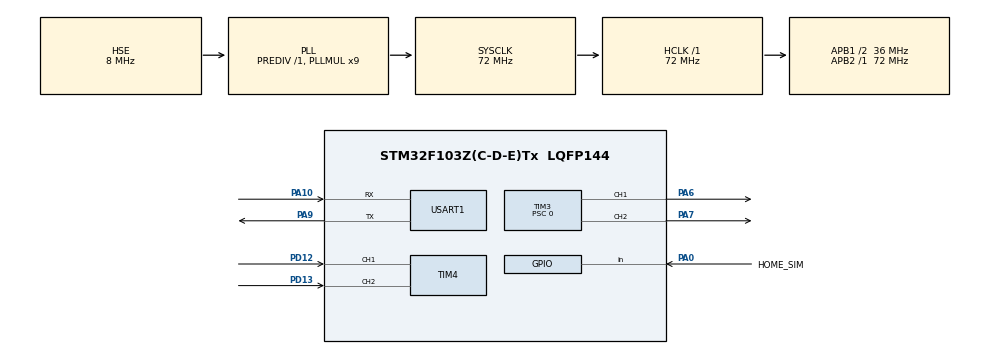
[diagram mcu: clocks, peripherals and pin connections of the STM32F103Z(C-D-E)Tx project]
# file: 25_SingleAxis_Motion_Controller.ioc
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FREERTOS.Tasks01=Motion_Task_,24,512,Motion_Task,Default,NULL,Dynamic,NULL,NULL
Mcu.Family=STM32F1
Mcu.Name=STM32F103Z(C-D-E)Tx
Mcu.Package=LQFP144
NVIC.PriorityGroup=NVIC_PRIORITYGROUP_4
NVIC.TIM6_IRQn=true\:15\:0\:false\:false\:true\:false\:false\:true\:true
NVIC.TimeBase=TIM6_IRQn
NVIC.TimeBaseIP=TIM6
OSC_IN.Mode=HSE-External-Oscillator
OSC_IN.Signal=RCC_OSC_IN
OSC_OUT.Mode=HSE-External-Oscillator
OSC_OUT.Signal=RCC_OSC_OUT
PA0-WKUP.GPIO_Label=HOME_SIM
PA0-WKUP.GPIO_PuPd=GPIO_PULLDOWN
PA0-WKUP.Signal=GPIO_Input
PA10.Mode=Asynchronous
PA10.Signal=USART1_RX
PA13.Mode=Serial_Wire
PA13.Signal=SYS_JTMS-SWDIO
PA14.Mode=Serial_Wire
PA14.Signal=SYS_JTCK-SWCLK
PA6.Signal=S_TIM3_CH1
PA7.Signal=S_TIM3_CH2
PA9.Mode=Asynchronous
PA9.Signal=USART1_TX
PD12.Signal=S_TIM4_CH1
PD13.Signal=S_TIM4_CH2
ProjectManager.HeapSize=0x200
ProjectManager.StackSize=0x400
ProjectManager.TargetToolchain=STM32CubeIDE
RCC.AHBFreq_Value=72000000
RCC.APB1CLKDivider=RCC_HCLK_DIV2
RCC.APB1Freq_Value=36000000
RCC.APB1TimFreq_Value=72000000
RCC.APB2Freq_Value=72000000
RCC.APB2TimFreq_Value=72000000
RCC.HCLKFreq_Value=72000000
RCC.PLLMUL=RCC_PLL_MUL9
RCC.PLLSourceVirtual=RCC_PLLSOURCE_HSE
RCC.SYSCLKFreq_VALUE=72000000
RCC.SYSCLKSource=RCC_SYSCLKSOURCE_PLLCLK
RCC.USBFreq_Value=72000000
SH.S_TIM3_CH1.0=TIM3_CH1,PWM Generation1 CH1
SH.S_TIM3_CH2.0=TIM3_CH2,PWM Generation2 CH2
SH.S_TIM4_CH1.0=TIM4_CH1,Encoder_Interface
SH.S_TIM4_CH2.0=TIM4_CH2,Encoder_Interface
TIM3.AutoReloadPreload=TIM_AUTORELOAD_PRELOAD_ENABLE
TIM3.Channel-PWM\ Generation1\ CH1=TIM_CHANNEL_1
TIM3.Channel-PWM\ Generation2\ CH2=TIM_CHANNEL_2
TIM3.Period=3599
TIM3.Prescaler=0
TIM4.EncoderMode=TIM_ENCODERMODE_TI12
TIM4.IC1Filter=5
TIM4.IC2Filter=5
TIM4.IC2Polarity=TIM_ICPOLARITY_RISING
USART1.VirtualMode=VM_ASYNC
VP_FREERTOS_VS_CMSIS_V2.Mode=CMSIS_V2
VP_SYS_VS_tim6.Mode=TIM6
VP_TIM3_VS_ClockSourceINT.Mode=Internal
board=custom

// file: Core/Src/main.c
/* USER CODE BEGIN Header */
/**
  ******************************************************************************
  * @file           : main.c
  * @brief          : Main program body
  ******************************************************************************
  * @attention
  *
  * Copyright (c) 2026 STMicroelectronics.
  * All rights reserved.
  *
  * This software is licensed under terms that can be found in the LICENSE file
  * in the root directory of this software component.
  * If no LICENSE file comes with this software, it is provided AS-IS.
  *
  ******************************************************************************
  */
/* USER CODE END Header */
#include "main.h"
#include "cmsis_os.h"
#include "tim.h"
#include "usart.h"
#include "gpio.h"

void SystemClock_Config(void);
void MX_FREERTOS_Init(void);

int main(void)
{

  /* MCU Configuration--------------------------------------------------------*/

  /* Reset of all peripherals, Initializes the Flash interface and the Systick. */
  HAL_Init();

  /* Configure the system clock */
  SystemClock_Config();

  /* Initialize all configured peripherals */
  MX_GPIO_Init();
  MX_USART1_UART_Init();
  MX_TIM3_Init();
  MX_TIM4_Init();

  /* Init scheduler */
  osKernelInitialize();

  /* Call init function for freertos objects (in cmsis_os2.c) */
  MX_FREERTOS_Init();

  /* Start scheduler */
  osKernelStart();

  /* We should never get here as control is now taken by the scheduler */

  /* Infinite loop */
  while (1)
  {

  }
}

void SystemClock_Config(void)
{
  RCC_OscInitTypeDef RCC_OscInitStruct = {0};
  RCC_ClkInitTypeDef RCC_ClkInitStruct = {0};

  /** Initializes the RCC Oscillators according to the specified parameters
  * in the RCC_OscInitTypeDef structure.
  */
  RCC_OscInitStruct.OscillatorType = RCC_OSCILLATORTYPE_HSE;
  RCC_OscInitStruct.HSEState = RCC_HSE_ON;
  RCC_OscInitStruct.HSEPredivValue = RCC_HSE_PREDIV_DIV1;
  RCC_OscInitStruct.HSIState = RCC_HSI_ON;
  RCC_OscInitStruct.PLL.PLLState = RCC_PLL_ON;
  RCC_OscInitStruct.PLL.PLLSource = RCC_PLLSOURCE_HSE;
  RCC_OscInitStruct.PLL.PLLMUL = RCC_PLL_MUL9;
  if (HAL_RCC_OscConfig(&RCC_OscInitStruct) != HAL_OK)
  {
    Error_Handler();
  }

  /** Initializes the CPU, AHB and APB buses clocks
  */
  RCC_ClkInitStruct.ClockType = RCC_CLOCKTYPE_HCLK|RCC_CLOCKTYPE_SYSCLK
                              |RCC_CLOCKTYPE_PCLK1|RCC_CLOCKTYPE_PCLK2;
  RCC_ClkInitStruct.SYSCLKSource = RCC_SYSCLKSOURCE_PLLCLK;
  RCC_ClkInitStruct.AHBCLKDivider = RCC_SYSCLK_DIV1;
  RCC_ClkInitStruct.APB1CLKDivider = RCC_HCLK_DIV2;
  RCC_ClkInitStruct.APB2CLKDivider = RCC_HCLK_DIV1;

  if (HAL_RCC_ClockConfig(&RCC_ClkInitStruct, FLASH_LATENCY_2) != HAL_OK)
  {
    Error_Handler();
  }
}

void HAL_TIM_PeriodElapsedCallback(TIM_HandleTypeDef *htim)
{
  if (htim->Instance == TIM6)
  {
    HAL_IncTick();
  }
}

void Error_Handler(void)
{
  __disable_irq();
  while (1)
  {
  }
}

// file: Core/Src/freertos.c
/* USER CODE BEGIN Header */
/**
  ******************************************************************************
  * File Name          : freertos.c
  * Description        : Code for freertos applications
  ******************************************************************************
  */
/* USER CODE END Header */

#include "main.h"
#include "cmsis_os.h"

/* USER CODE BEGIN Includes */
#include "motion.h"
/* USER CODE END Includes */

/* Definitions for Motion_Task_ */
osThreadId_t Motion_Task_Handle;
const osThreadAttr_t Motion_Task__attributes = {
  .name = "Motion_Task_",
  .stack_size = 512 * 4,
  .priority = (osPriority_t) osPriorityNormal,
};

void Motion_Task(void *argument);
void MX_FREERTOS_Init(void); /* (MISRA C 2004 rule 8.1) */

void MX_FREERTOS_Init(void)
{
  /* USER CODE BEGIN Init */
	// 在创建任务前完成运动模块的外设启动与状态清零
	Motion_Init();

  /* USER CODE END Init */

  /* Create the thread(s) */
  /* creation of Motion_Task_ */
  Motion_Task_Handle = osThreadNew(Motion_Task, NULL, &Motion_Task__attributes);
}

void Motion_Task(void *argument)
{
  /* USER CODE BEGIN Motion_Task */
	// osDelayUntil 使用绝对 tick，避免循环执行耗时逐步累积成周期漂移
	uint32_t next_wake_tick = osKernelGetTickCount();

	for(;;)
	{
		// 单一任务统一拥有运动状态、控制计算和 PWM 输出
		Motion_Update();

		next_wake_tick += 20;
		osDelayUntil(next_wake_tick);
	}
  /* USER CODE END Motion_Task */
}
